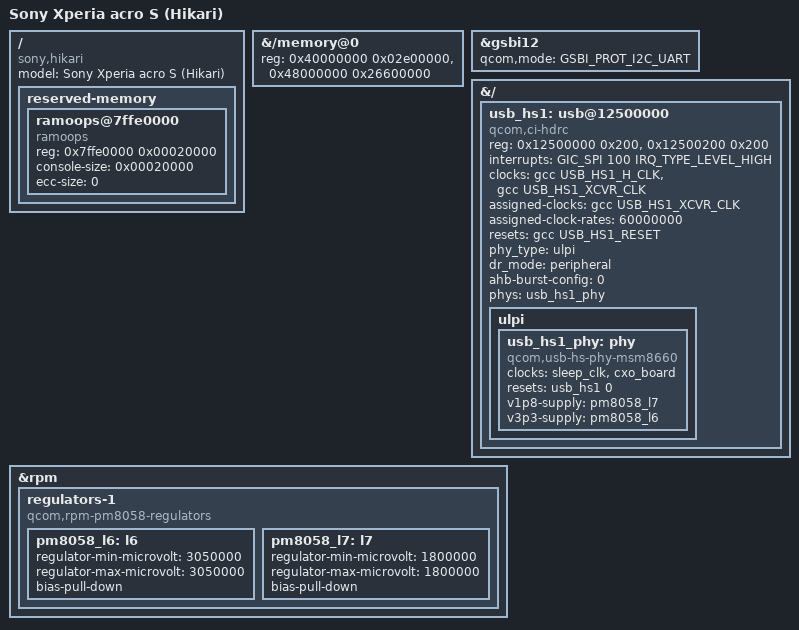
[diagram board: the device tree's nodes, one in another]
// SPDX-License-Identifier: GPL-2.0
/dts-v1/;

#include <dt-bindings/soc/qcom,gsbi.h>
#include <dt-bindings/reset/qcom,gcc-msm8660.h>
#include "qcom-msm8660.dtsi"

/ {
	model = "Sony Xperia acro S (Hikari)";
	compatible = "sony,hikari", "qcom,msm8660";

	/*
	 * The legacy Fuji/TWRP kernel and a physical TWRP /proc/iomem capture
	 * both identify this as the 128 KiB persistent ram_console region.
	 * Keep it mapped: ramoops writes the console itself.  Its zero ECC layout
	 * is deliberately compatible with the legacy TWRP ram_console reader.
	 */
	reserved-memory {
		#address-cells = <1>;
		#size-cells = <1>;
		ranges;

		ramoops@7ffe0000 {
			compatible = "ramoops";
			reg = <0x7ffe0000 0x00020000>;
			console-size = <0x00020000>;
			ecc-size = <0>;
		};
	};

	/*
	 * The low bank starts at the historical MSM8x60 shared-memory physical
	 * base.  CONFIG_ARCH_QCOM_RESERVE_SMEM then retains its first 2 MiB for
	 * SMEM, leaving 0x40200000 as the first normal Linux address.  The legacy
	 * resource view starts at that latter address; see FIRST_BOOT_MEMORY.md.
	 * This remains a deliberately minimal bring-up memory description, not a
	 * claim that every byte of nominal RAM is currently understood.
	 */
};

/* Override the placeholder System RAM node supplied by qcom-msm8660.dtsi. */
&{/memory@0} {
	reg = <0x40000000 0x02e00000>,
	      <0x48000000 0x26600000>;
};

/*
 * The legacy kernel directly observed a low-speed UART at 0x19c40000.  Keep
 * this common-SoC GSBI disabled until a physical console route is known; its
 * required mux property is nevertheless part of a schema-valid description.
 */
&gsbi12 {
	qcom,mode = <GSBI_PROT_I2C_UART>;
};

/*
 * HSUSB1 is the connector-facing ChipIdea controller.  The address and IRQ
 * are shared MSM8x60 facts; `peripheral` and the two PHY rails come from the
 * Fuji/Hikari downstream board code.  PMIC VBUS/ID callbacks were only used
 * for legacy OTG role switching, so BOOT #5 deliberately supports device
 * mode only and does not invent an extcon or host-role GPIO description.
 */
&{/} {
	usb_hs1: usb@12500000 {
		compatible = "qcom,ci-hdrc";
		reg = <0x12500000 0x200>, <0x12500200 0x200>;
		interrupts = <GIC_SPI 100 IRQ_TYPE_LEVEL_HIGH>;
		clocks = <&gcc USB_HS1_H_CLK>, <&gcc USB_HS1_XCVR_CLK>;
		clock-names = "iface", "core";
		assigned-clocks = <&gcc USB_HS1_XCVR_CLK>;
		assigned-clock-rates = <60000000>;
		resets = <&gcc USB_HS1_RESET>;
		reset-names = "core";
		phy_type = "ulpi";
		dr_mode = "peripheral";
		ahb-burst-config = <0>;
		phys = <&usb_hs1_phy>;
		phy-names = "usb-phy";
		#reset-cells = <1>;
		status = "okay";

		ulpi {
			usb_hs1_phy: phy {
				compatible = "qcom,usb-hs-phy-msm8660",
					     "qcom,usb-hs-phy";
				clocks = <&sleep_clk>, <&cxo_board>;
				clock-names = "sleep", "ref";
				resets = <&usb_hs1 0>;
				reset-names = "por";
				v1p8-supply = <&pm8058_l7>;
				v3p3-supply = <&pm8058_l6>;
				#phy-cells = <0>;
			};
		};
	};
};

/* Exact PHY rails and operating voltages from the Hikari downstream BSP. */
&rpm {
	regulators-1 {
		compatible = "qcom,rpm-pm8058-regulators";

		pm8058_l6: l6 {
			regulator-min-microvolt = <3050000>;
			regulator-max-microvolt = <3050000>;
			bias-pull-down;
		};

		pm8058_l7: l7 {
			regulator-min-microvolt = <1800000>;
			regulator-max-microvolt = <1800000>;
			bias-pull-down;
		};
	};
};
